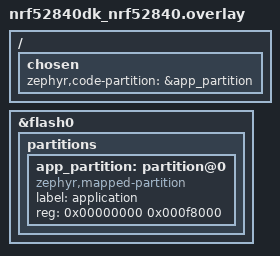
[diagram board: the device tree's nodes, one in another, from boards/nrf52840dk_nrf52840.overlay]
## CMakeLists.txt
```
cmake_minimum_required(VERSION 3.20.0)

find_package(Zephyr REQUIRED HINTS $ENV{ZEPHYR_BASE})
project(ErgoTypeNRF C)

target_compile_definitions(app PRIVATE ERGOTYPE_ZEPHYR=1)

target_include_directories(app PRIVATE
    ${CMAKE_CURRENT_LIST_DIR}
    ${CMAKE_CURRENT_LIST_DIR}/coreJSON/source/include
    ${CMAKE_CURRENT_LIST_DIR}/pointing
    ${CMAKE_CURRENT_LIST_DIR}/pointing/pmw3360
    ${CMAKE_CURRENT_LIST_DIR}/pointing/pmw3389
)

target_compile_options(app PRIVATE
    -iquote${CMAKE_CURRENT_LIST_DIR}/keyd/port
    -iquote${CMAKE_CURRENT_LIST_DIR}/keyd/src
)

set_source_files_properties(keyd/port/config.c PROPERTIES COMPILE_OPTIONS -Wno-comment)

target_sources(app PRIVATE
    src/main.c
    src/keyscan_zephyr.c
    src/log_zephyr.c
    src/pointing_zephyr.c
    src/ui_zephyr.c
    display/ssd1306.c
    coreJSON/source/core_json.c
    keyd/src/keys.c
    keyd/src/string.c
    keyd/src/unicode.c
    keyd/port/config.c
    keyd/port/daemon.c
    keyd/port/evloop.c
    keyd/port/hooks.c
    keyd/port/keyboard.c
    keyd/port/macro.c
    keyd/port/task.c
    keyd/port/vkbd/tusb_hid.c
    keyd/port/vkbd/vkbd.c
    jconfig.c
    pointing/accel/filter.c
    pointing/accel/filter-adaptive.c
    pointing/accel/filter-adaptive-high-dpi.c
    pointing/accel/filter-adaptive-low-dpi.c
    pointing/accel/filter-custom.c
    pointing/accel/filter-flat.c
    pointing/pmw3360/pmw3360.c
    pointing/pmw3360/srom.c
    pointing/pmw3389/pmw3389.c
    pointing/pmw3389/srom.c
    platform/zephyr/ble.c
    platform/zephyr/ble_config.c
    platform/zephyr/ble_log.c
    platform/zephyr/events.c
    platform/zephyr/gpio.c
    platform/zephyr/hid.c
    platform/zephyr/i2c.c
    platform/zephyr/os.c
    platform/zephyr/spi.c
    platform/zephyr/storage.c
    platform/zephyr/time.c
    platform/zephyr/vkbd_events.c
    platform/zephyr/ws2812.c
)
```

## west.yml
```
manifest:
  remotes:
    - name: nrfconnect
      url-base: https://github.com/nrfconnect
  projects:
    - name: nrf
      remote: nrfconnect
      repo-path: sdk-nrf
      revision: v3.4.0
      import: true
  self:
    path: app
```

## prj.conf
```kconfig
CONFIG_MAIN_STACK_SIZE=4096
CONFIG_SYSTEM_WORKQUEUE_STACK_SIZE=2048
CONFIG_HEAP_MEM_POOL_SIZE=32768
CONFIG_THREAD_NAME=y
CONFIG_POLL=y
CONFIG_EVENTS=y
CONFIG_LOG=y
CONFIG_CONSOLE=y
CONFIG_SERIAL=y

CONFIG_GPIO=y
CONFIG_NRFX_PWM=y
CONFIG_NRFX_SPIM=y
CONFIG_NRFX_TWIM=y
CONFIG_BT=y
CONFIG_BT_SMP=y
CONFIG_BT_PERIPHERAL=y
CONFIG_BT_DIS=y
CONFIG_BT_BAS=y
CONFIG_BT_DEVICE_NAME="ErgoTypeNRF"
CONFIG_BT_DEVICE_APPEARANCE=961
CONFIG_BT_SETTINGS=y
CONFIG_BT_L2CAP_TX_MTU=66
CONFIG_BT_BUF_ACL_TX_SIZE=70
CONFIG_BT_BUF_ACL_RX_SIZE=70
CONFIG_FLASH=y
CONFIG_FLASH_MAP=y
CONFIG_FILE_SYSTEM=y
CONFIG_FILE_SYSTEM_LITTLEFS=y
CONFIG_SETTINGS=y
CONFIG_SETTINGS_FILE=y
CONFIG_SETTINGS_FILE_PATH="/lfs/settings"
CONFIG_USE_DT_CODE_PARTITION=y
```

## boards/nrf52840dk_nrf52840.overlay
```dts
/ {
	chosen {
		zephyr,code-partition = &app_partition;
	};
};

&flash0 {
	partitions {
		/delete-node/ partition@0;
		/delete-node/ partition@c000;
		/delete-node/ partition@82000;

		app_partition: partition@0 {
			compatible = "zephyr,mapped-partition";
			label = "application";
			reg = <0x00000000 0x000f8000>;
		};
	};
};
```

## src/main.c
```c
#include <stdbool.h>

#include <zephyr/kernel.h>
#include <zephyr/logging/log.h>

#include "jconfig.h"
#include "platform/ble.h"
#include "platform/events.h"
#include "platform/os.h"
#include "platform/storage.h"
#include "platform/vkbd_events.h"
#include "pointing/pointer.h"
#include "keys.h"
#include "ui/ui.h"

LOG_MODULE_REGISTER(ergotype_nrf, LOG_LEVEL_INF);

extern const char *keyd_overlay_conf;

K_THREAD_STACK_DEFINE(keyscan_stack, 2048);
K_THREAD_STACK_DEFINE(keyd_stack, 8192);
K_THREAD_STACK_DEFINE(pointing_stack, 4096);
K_THREAD_STACK_DEFINE(ui_stack, 2048);
K_THREAD_STACK_DEFINE(vkbd_hid_stack, 4096);

void keyscan_task(void *arg);
uint8_t count_pressed_keys(config_t *config, uint8_t *single_code);
void keyd_task(void *arg);
void vkbd_hid_nkro_task(void *arg);

void on_layout_change(const char *name)
{
    ui_notify_layout(name);
}

static void select_profile(uint8_t code)
{
    switch (code) {
    case KEYD_A:
        keyd_overlay_conf = "android.conf";
        break;
    case KEYD_W:
        keyd_overlay_conf = "windows.conf";
        break;
    case KEYD_M:
        keyd_overlay_conf = "macos.conf";
        break;
    case KEYD_D:
        keyd_overlay_conf = NULL;
        break;
    default:
        return;
    }
}

int main(void)
{
    LOG_INF("ErgoTypeNRF boot");

    int rc = platform_storage_mount();
    if (rc) {
        LOG_WRN("storage mount failed: %d", rc);
    }

    static config_t config;
    bool config_loaded = false;
    rc = parse(&config, "config.json");
    if (rc == 0) {
        uint8_t startup_key = 0;
        uint8_t nr_pressed = count_pressed_keys(&config, &startup_key);
        select_profile(startup_key);
        config_loaded = true;

        LOG_INF("config loaded: rows=%u cols=%u encoders=%u pmw3360=%u pmw3389=%u",
                config.matrix.nr_rows,
                config.matrix.nr_cols,
                config.nr_encoders,
                config.nr_pmw3360,
                config.nr_pmw3389);
        LOG_INF("startup keys: count=%u key=%u", nr_pressed, startup_key);
    } else {
        LOG_WRN("config.json not loaded; keyboard runtime is not started yet");
    }

    rc = platform_ble_start();
    if (rc) {
        LOG_ERR("BLE start failed: %d", rc);
        return rc;
    }

    LOG_INF("BLE advertising started");

    if (config_loaded) {
        rc = platform_input_events_init();
        if (rc) {
            LOG_ERR("input event queue init failed: %d", rc);
            return rc;
        }
        rc = platform_vkbd_events_init();
        if (rc) {
            LOG_ERR("vkbd event queue init failed: %d", rc);
            return rc;
        }

        rc = platform_task_start("keyscan", keyscan_task, &config,
                                 keyscan_stack, K_THREAD_STACK_SIZEOF(keyscan_stack),
                                 K_PRIO_PREEMPT(3));
        if (rc) {
            LOG_ERR("keyscan task start failed: %d", rc);
            return rc;
        }
        if (config.nr_leds != 0 || config.ws2812_pin != -1 || config.ssd1306.i2c_idx != -1) {
            rc = platform_task_start("ui", ui_task, &config,
                                     ui_stack, K_THREAD_STACK_SIZEOF(ui_stack),
                                     K_PRIO_PREEMPT(5));
            if (rc) {
                LOG_ERR("ui task start failed: %d", rc);
                return rc;
            }
        }
        if (config.nr_pmw3360 || config.nr_pmw3389) {
            rc = platform_task_start("pointing", pointing_device_task, &config,
                                     pointing_stack, K_THREAD_STACK_SIZEOF(pointing_stack),
                                     K_PRIO_PREEMPT(1));
            if (rc) {
                LOG_ERR("pointing task start failed: %d", rc);
                return rc;
            }
        }
        rc = platform_task_start("vkbd-hid", vkbd_hid_nkro_task, NULL,
                                 vkbd_hid_stack, K_THREAD_STACK_SIZEOF(vkbd_hid_stack),
                                 K_PRIO_PREEMPT(4));
        if (rc) {
            LOG_ERR("vkbd HID task start failed: %d", rc);
            return rc;
        }
        rc = platform_task_start("keyd", keyd_task, NULL,
                                 keyd_stack, K_THREAD_STACK_SIZEOF(keyd_stack),
                                 K_PRIO_PREEMPT(2));
        if (rc) {
            LOG_ERR("keyd task start failed: %d", rc);
            return rc;
        }
    }

    for (;;) {
        k_sleep(K_SECONDS(60));
    }
}
```

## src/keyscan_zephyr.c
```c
#include <stdbool.h>
#include <stdint.h>

#include "device.h"
#include "jconfig.h"
#include "keys.h"
#include "platform/events.h"
#include "platform/gpio.h"
#include "platform/time.h"

static uint8_t debouncing_time;
static bool debouncing;

typedef struct {
    uint8_t prev;
    int16_t accum;
} encoder_state_t;

static bool is_encoder_channel(const config_t *config, uint8_t row, uint8_t col)
{
    for (uint8_t i = 0; i < config->nr_encoders; ++i) {
        const encoder_t *enc = &config->encoders[i];
        if ((row == enc->a && col == enc->c) || (row == enc->b && col == enc->c))
            return true;
    }
    return false;
}

static inline bool matrix_pressed(const matrix_row_t *matrix, uint8_t row, uint8_t col)
{
    return (matrix[row] & ((matrix_row_t)1 << col)) != 0;
}

static void send_key_tap(uint8_t code)
{
    struct device_event ev = {0};
    ev.type = DEV_KEY;
    ev.code = code;

    ev.pressed = 1;
    platform_input_event_send(&ev, PLATFORM_EVENT_WAIT_FOREVER);
    ev.pressed = 0;
    platform_input_event_send(&ev, PLATFORM_EVENT_WAIT_FOREVER);
}

static void process_encoders(const config_t *config,
                             encoder_state_t *states,
                             const matrix_row_t *raw_matrix)
{
    static const int8_t quad_table[16] = {
        0, -1, 1, 0,
        1, 0, 0, -1,
        -1, 0, 0, 1,
        0, 1, -1, 0,
    };

    for (uint8_t i = 0; i < config->nr_encoders; ++i) {
        const encoder_t *enc = &config->encoders[i];
        encoder_state_t *st = &states[i];

        uint8_t curr = 0;
        if (matrix_pressed(raw_matrix, enc->a, enc->c))
            curr |= 0x1;
        if (matrix_pressed(raw_matrix, enc->b, enc->c))
            curr |= 0x2;

        if (st->prev == 0xFF) {
            st->prev = curr;
            st->accum = 0;
            continue;
        }

        uint8_t idx = (uint8_t)((st->prev << 2) | curr);
        int16_t delta = quad_table[idx];

        st->prev = curr;
        if (delta > 0 && st->accum < 0)
            st->accum = 0;
        else if (delta < 0 && st->accum > 0)
            st->accum = 0;
        st->accum += delta;

        while (st->accum >= (int16_t)enc->div) {
            st->accum -= (int16_t)enc->div;
            send_key_tap(config->matrix.keymap[enc->a][enc->c]);
        }
        while (st->accum <= -(int16_t)enc->div) {
            st->accum += (int16_t)enc->div;
            send_key_tap(config->matrix.keymap[enc->b][enc->c]);
        }
    }
}

static const uint8_t row2col = 0;
static uint8_t col2row = 1;

static void select_row(matrix_t *matrix, uint8_t row)
{
    platform_gpio_output(matrix->gpio_rows[row], false);
}

static void unselect_row(matrix_t *matrix, uint8_t row)
{
    platform_gpio_input_pullup(matrix->gpio_rows[row]);
}

static void select_col(matrix_t *matrix, uint8_t col)
{
    platform_gpio_output(matrix->gpio_cols[col], false);
}

static void unselect_col(matrix_t *matrix, uint8_t col)
{
    platform_gpio_input_pullup(matrix->gpio_cols[col]);
}

void matrix_init(matrix_t *matrix)
{
    if (col2row) {
        for (uint8_t row = 0; row < matrix->nr_rows; row++)
            unselect_row(matrix, row);
        for (uint8_t col = 0; col < matrix->nr_cols; col++)
            unselect_col(matrix, col);
    } else if (row2col) {
        for (uint8_t col = 0; col < matrix->nr_cols; col++)
            unselect_col(matrix, col);
        for (uint8_t row = 0; row < matrix->nr_rows; row++)
            unselect_row(matrix, row);
    } else {
        for (uint8_t row = 0; row < matrix->nr_rows; row++)
            unselect_row(matrix, row);
        for (uint8_t col = 0; col < matrix->nr_cols; col++)
            platform_gpio_input_pullup(matrix->gpio_cols[col]);
    }
}

static inline bool popcount_more_than_one(matrix_row_t rowdata)
{
    rowdata &= rowdata - 1;
    return rowdata != 0;
}

static matrix_row_t get_real_keys(matrix_t *matrix, uint8_t row, matrix_row_t rowdata)
{
    matrix_row_t out = 0;
    for (uint8_t col = 0; col < matrix->nr_cols; col++) {
        if (matrix->keymap[row][col] && (rowdata & ((matrix_row_t)1 << col)))
            out |= ((matrix_row_t)1 << col);
    }
    return out;
}

static bool has_ghost_in_row(matrix_t *matrix, uint8_t row, matrix_row_t rowdata,
                             matrix_row_t *current_matrix)
{
    if (col2row || row2col)
        return false;
    rowdata = get_real_keys(matrix, row, rowdata);
    if (!popcount_more_than_one(rowdata))
        return false;
    for (uint8_t i = 0; i < matrix->nr_rows; i++) {
        if (i != row && popcount_more_than_one(get_real_keys(matrix, i, current_matrix[i]) & rowdata))
            return true;
    }
    return false;
}

void matrix_scan(matrix_t *matrix, matrix_row_t *raw_matrix)
{
    if (col2row) {
        for (uint8_t row = 0; row < matrix->nr_rows; row++) {
            matrix_row_t row_value = 0;
            select_row(matrix, row);
            platform_sleep_us(20);
            for (uint8_t col = 0; col < matrix->nr_cols; col++) {
                int pin_state = platform_gpio_read(matrix->gpio_cols[col]);
                if (pin_state == 0)
                    row_value |= ((matrix_row_t)1 << col);
            }
            unselect_row(matrix, row);
            raw_matrix[row] = row_value;
        }
    } else if (row2col) {
        for (uint8_t col = 0; col < matrix->nr_cols; col++) {
            matrix_row_t col_mask = ((matrix_row_t)1 << col);
            select_col(matrix, col);
            platform_sleep_us(20);
            for (uint8_t row = 0; row < matrix->nr_rows; row++) {
                int pin_state = platform_gpio_read(matrix->gpio_rows[row]);
                if (pin_state == 0)
                    raw_matrix[row] |= col_mask;
                else
                    raw_matrix[row] &= ~col_mask;
            }
            unselect_col(matrix, col);
        }
    } else {
        for (uint8_t row = 0; row < matrix->nr_rows; row++) {
            matrix_row_t row_value = 0;
            uint8_t row_pin = matrix->gpio_rows[row];
            platform_gpio_output(row_pin, false);

            for (uint8_t r = 0; r < matrix->nr_rows; r++) {
                if (r != row)
                    platform_gpio_input_pullup(matrix->gpio_rows[r]);
            }
            platform_sleep_us(20);
            for (uint8_t col = 0; col < matrix->nr_cols; col++) {
                int pin_state = platform_gpio_read(matrix->gpio_cols[col]);
                if (pin_state == 0)
                    row_value |= ((matrix_row_t)1 << col);
            }
            platform_gpio_input_pullup(row_pin);
            raw_matrix[row] = row_value;
        }
    }
}

bool debounce(matrix_row_t *raw_matrix, matrix_row_t *debounced_matrix, uint8_t nr_rows)
{
    static matrix_row_t matrix_debouncing[MAX_GPIOS];
    static uint32_t last_update;
    bool changed = false;

    for (uint8_t i = 0; i < nr_rows; i++) {
        if (matrix_debouncing[i] != raw_matrix[i]) {
            matrix_debouncing[i] = raw_matrix[i];
            debouncing = true;
            last_update = platform_uptime_ms();
        }
    }

    if (debouncing && (platform_uptime_ms() - last_update > debouncing_time)) {
        for (uint8_t i = 0; i < nr_rows; i++) {
            if (debounced_matrix[i] != matrix_debouncing[i]) {
                debounced_matrix[i] = matrix_debouncing[i];
                changed = true;
            }
        }
        debouncing = false;
    }

    return changed;
}

uint8_t count_pressed_keys(config_t *config, uint8_t *single_code)
{
    matrix_row_t raw_matrix[MAX_GPIOS] = {0};
    uint8_t pressed_count = 0;
    uint8_t code = 0;

    matrix_init(&config->matrix);
    matrix_scan(&config->matrix, raw_matrix);

    for (uint8_t row = 0; row < config->matrix.nr_rows; row++) {
        for (uint8_t col = 0; col < config->matrix.nr_cols; col++) {
            if (raw_matrix[row] & ((matrix_row_t)1 << col)) {
                if (!is_encoder_channel(config, row, col)) {
                    pressed_count++;
                    if (pressed_count == 1)
                        code = config->matrix.keymap[row][col];
                }
            }
        }
    }

    *single_code = pressed_count == 1 ? code : 0;
    return pressed_count;
}

void keyscan_task(void *arg)
{
    config_t *config = arg;
    debouncing_time = config->debounce;
    debouncing = debouncing_time > 0;
    static matrix_row_t raw_matrix[MAX_GPIOS];
    static matrix_row_t debounced_matrix[MAX_GPIOS];
    static matrix_row_t previous_debounced_matrix[MAX_GPIOS];
    static encoder_state_t encoder_states[MAX_ENCODERS];
    struct device_event devev = {
        .type = DEV_KEY,
    };

    matrix_init(&config->matrix);
    for (uint8_t i = 0; i < MAX_ENCODERS; ++i) {
        encoder_states[i].prev = 0xFF;
        encoder_states[i].accum = 0;
    }

    for (;;) {
        uint32_t started = platform_uptime_ms();
        matrix_scan(&config->matrix, raw_matrix);
        if (config->nr_encoders > 0)
            process_encoders(config, encoder_states, raw_matrix);

        bool debounced_changed = debounce(raw_matrix, debounced_matrix, config->matrix.nr_rows);
        if (debounced_changed) {
            for (uint8_t row = 0; row < config->matrix.nr_rows; row++) {
                matrix_row_t changed_keys = debounced_matrix[row] ^ previous_debounced_matrix[row];
                if (!changed_keys) {
                    previous_debounced_matrix[row] = debounced_matrix[row];
                    continue;
                }
                if (has_ghost_in_row(&config->matrix, row, debounced_matrix[row], debounced_matrix)) {
                    debounced_matrix[row] = 0;
                    previous_debounced_matrix[row] = debounced_matrix[row];
                    continue;
                }
                for (uint8_t col = 0; col < config->matrix.nr_cols; col++) {
                    matrix_row_t col_mask = ((matrix_row_t)1 << col);
                    if (!(changed_keys & col_mask))
                        continue;
                    if (is_encoder_channel(config, row, col))
                        continue;

                    devev.pressed = (debounced_matrix[row] & col_mask) != 0;
                    devev.code = config->matrix.keymap[row][col];
                    platform_input_event_send(&devev, PLATFORM_EVENT_WAIT_FOREVER);
                }
                previous_debounced_matrix[row] = debounced_matrix[row];
            }
        }

        uint32_t elapsed = platform_uptime_ms() - started;
        if (elapsed < (uint32_t)config->scan_period)
            platform_sleep_ms((uint32_t)config->scan_period - elapsed);
    }
}
```

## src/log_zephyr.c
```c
#include "log.h"

#include <stdbool.h>
#include <stdio.h>
#include <string.h>

#include <zephyr/sys/printk.h>

#include "platform/ble_log.h"
#include "ui/ui.h"

int log_level = 0;
int suppress_colours = 1;

static void strip_markup(const char *input, char *output, size_t output_size)
{
    size_t out = 0;
    bool inside_markup = false;

    for (size_t i = 0; input[i] != '\0' && out + 1u < output_size; ++i) {
        if (input[i + 1u] == '{' && strchr("rgybmcw", input[i])) {
            inside_markup = true;
            ++i;
            continue;
        }
        if (input[i] == '}' && inside_markup) {
            inside_markup = false;
            continue;
        }
        output[out++] = input[i];
    }

    output[out] = '\0';
}

void _msg(int level, log_kind_t kind, const char *fmt, ...)
{
    if (level > log_level)
        return;

    switch (kind) {
    case LOG_KIND_WARN:
        ui_notify_warn();
        break;
    case LOG_KIND_ERR:
        ui_notify_err();
        break;
    case LOG_KIND_MSG:
        break;
    }

    char clean_fmt[160];
    char line[160];
    strip_markup(fmt, clean_fmt, sizeof(clean_fmt));

    va_list ap;
    va_start(ap, fmt);
    int n = vsnprintf(line, sizeof(line), clean_fmt, ap);
    va_end(ap);

    if (n <= 0)
        return;

    size_t length = (size_t)n < sizeof(line) ? (size_t)n : sizeof(line) - 1u;
    printk("%s", line);
    platform_ble_log_write(line, length);
}
```

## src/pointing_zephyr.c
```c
#include <stdint.h>

#include <zephyr/kernel.h>
#include <zephyr/sys/atomic.h>

#include "accel/filter.h"
#include "device.h"
#include "jconfig.h"
#include "log.h"
#include "platform/events.h"
#include "platform/gpio.h"
#include "platform/spi.h"
#include "platform/time.h"
#include "pointing/pointer.h"
#include "pmw3360.h"
#include "pmw3389.h"

static struct k_poll_signal motion_signal;
static atomic_t motion_bits;

static int32_t x125pct(int32_t value)
{
    int32_t magnitude = value < 0 ? -value : value;
    // Add 25%: shifting the magnitude right by 2 divides it by 4.
    magnitude += magnitude >> 2;

    return value < 0 ? -magnitude : magnitude;
}

static int32_t scaled_to_q10(int32_t value, int32_t scale)
{
    int32_t whole = value / scale;
    int32_t rem = value % scale;
    int32_t q10 = whole * Q10_ONE;

    if (rem < 0)
        q10 -= ((-rem * Q10_ONE) + scale / 2) / scale;
    else
        q10 += (rem * Q10_ONE + scale / 2) / scale;

    return q10;
}

static void accel_prepare(accel_profile_cfg_t *accel)
{
    switch (accel->profile) {
    case ACCEL_PROFILE_NONE:
        return;
    case ACCEL_PROFILE_FLAT:
    case ACCEL_PROFILE_ADAPTIVE:
        accel->speed = scaled_to_q10(accel->speed, accel->scale);
        return;
    case ACCEL_PROFILE_CUSTOM:
        return;
    }
}

static void motion_irq(platform_gpio_t pin, void *user)
{
    (void)pin;

    uint32_t bits = (uint32_t)(uintptr_t)user;
    atomic_or(&motion_bits, (atomic_val_t)bits);
    k_poll_signal_raise(&motion_signal, 1);
}

void pointing_motion_irq_init(void *task_handle, int8_t mot_pin, uint8_t sensor_idx)
{
    (void)task_handle;

    uint32_t bit = 1u << sensor_idx;
    platform_gpio_irq_falling(mot_pin, motion_irq, (void *)(uintptr_t)bit);
}

static void spi_bus_init_once(uint8_t bus, const config_t *config)
{
    platform_spi_init(bus,
                      config->spi[bus].sck,
                      config->spi[bus].mosi,
                      config->spi[bus].miso,
                      config->spi[bus].baud);
}

void pointing_device_task(void *arg)
{
    config_t *config = arg;
    struct filter_state *pmw3360_filters = NULL;
    struct filter_state *pmw3389_filters = NULL;
    accel_prepare(&config->move_accel);
    accel_prepare(&config->scroll_accel);

    if (config->nr_pmw3360) {
        pmw3360_filters = k_malloc(sizeof(*pmw3360_filters) * config->nr_pmw3360);
        __ASSERT_NO_MSG(pmw3360_filters);
    }

    if (config->nr_pmw3389) {
        pmw3389_filters = k_malloc(sizeof(*pmw3389_filters) * config->nr_pmw3389);
        __ASSERT_NO_MSG(pmw3389_filters);
    }

    k_poll_signal_init(&motion_signal);

    for (uint8_t bus = 0; bus < MAX_SPI; ++bus) {
        if (config->spi_mask & (uint8_t)(1u << bus))
            spi_bus_init_once(bus, config);
    }

    for (uint8_t i = 0; i < config->nr_pmw3360; ++i) {
        pmw3360_init(&config->pmw3360[i]);
        pmw3360_set_cpi(&config->pmw3360[i]);
        uint8_t role = config->pmw3360[i].role;
        filter_init(&pmw3360_filters[i],
                    role == SENSOR_ROLE_SCROLL ? &config->scroll_accel : &config->move_accel,
                    config->pmw3360[i].cpi);
        pointing_motion_irq_init(NULL, config->pmw3360[i].irq, i);
    }

    for (uint8_t i = 0; i < config->nr_pmw3389; ++i) {
        pmw3389_init(&config->pmw3389[i]);
        pmw3389_set_cpi(&config->pmw3389[i]);
        uint8_t role = config->pmw3389[i].role;
        filter_init(&pmw3389_filters[i],
                    role == SENSOR_ROLE_SCROLL ? &config->scroll_accel : &config->move_accel,
                    config->pmw3389[i].cpi);
        pointing_motion_irq_init(NULL, config->pmw3389[i].irq, (uint8_t)(MAX_PMW3360 + i));
    }

    struct k_poll_event event = K_POLL_EVENT_INITIALIZER(K_POLL_TYPE_SIGNAL,
                                                         K_POLL_MODE_NOTIFY_ONLY,
                                                         &motion_signal);

    for (;;) {
        k_poll(&event, 1, K_FOREVER);
        k_poll_signal_reset(&motion_signal);
        event.state = K_POLL_STATE_NOT_READY;

        platform_sleep_ms(1);

        uint32_t bits = (uint32_t)atomic_set(&motion_bits, 0);
        int mouse_dx_sum = 0;
        int mouse_dy_sum = 0;
        int scroll_dx_sum = 0;
        int scroll_dy_sum = 0;
        struct device_event devev = {0};

        for (uint8_t i = 0; i < config->nr_pmw3360; ++i) {
            if (bits && !(bits & (1u << i)))
                continue;
            int16_t dx = 0;
            int16_t dy = 0;
            pmw3360_get_deltas(&config->pmw3360[i], &dx, &dy);
            // Temporary transform for the current trackball prototype, whose sensor is mounted at 30 degrees.
            // This may move to config if per-device coordinate transforms are needed.
            int32_t x = x125pct(dx);
            int32_t y = -dy;
            uint8_t role = config->pmw3360[i].role;
            filter_process(&pmw3360_filters[i], &x, &y);
            if (role == SENSOR_ROLE_SCROLL) {
                scroll_dx_sum += x;
                scroll_dy_sum += y;
            } else {
                mouse_dx_sum += x;
                mouse_dy_sum += y;
            }
        }

        for (uint8_t i = 0; i < config->nr_pmw3389; ++i) {
            if (bits && !(bits & (1u << (MAX_PMW3360 + i))))
                continue;
            int16_t dx = 0;
            int16_t dy = 0;
            pmw3389_get_deltas(&config->pmw3389[i], &dx, &dy);
            // Temporary transform for the current trackball prototype, whose sensor is mounted at 30 degrees.
            // This may move to config if per-device coordinate transforms are needed.
            int32_t x = x125pct(dx);
            int32_t y = -dy;
            uint8_t role = config->pmw3389[i].role;
            filter_process(&pmw3389_filters[i], &x, &y);
            if (role == SENSOR_ROLE_SCROLL) {
                scroll_dx_sum += x;
                scroll_dy_sum += y;
            } else {
                mouse_dx_sum += x;
                mouse_dy_sum += y;
            }
        }

        if (mouse_dx_sum || mouse_dy_sum) {
            devev.type = DEV_MOUSE_MOVE;
            devev.x = mouse_dx_sum;
            devev.y = mouse_dy_sum;
            platform_input_event_send(&devev, PLATFORM_EVENT_WAIT_FOREVER);
        }
        if (scroll_dx_sum || scroll_dy_sum) {
            devev.type = DEV_MOUSE_SCROLL;
            devev.x = scroll_dx_sum;
            devev.y = scroll_dy_sum;
            platform_input_event_send(&devev, PLATFORM_EVENT_WAIT_FOREVER);
        }
    }
}
```

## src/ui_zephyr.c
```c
#include "ui/ui.h"

#include <stdio.h>
#include <string.h>

#include <zephyr/kernel.h>

#include "display/px6x8_font.h"
#include "display/ssd1306.h"
#include "jconfig.h"
#include "led/ws2812.h"
#include "platform/gpio.h"
#include "platform/i2c.h"

#define UI_STEP_MS 100u
#define UI_TITLE_LEN (sizeof(ui_title) - 1u)
#define UI_TITLE_WIDTH_PX (UI_TITLE_LEN * 6u)
#define UI_TITLE_WIN_COLS 4u
#define UI_TITLE_WIN_PX (UI_TITLE_WIN_COLS * 6u)
#define UI_STATUS_MODE_LEN 3u
#define UI_STATUS_MODE_COL (UI_TITLE_WIN_COLS + 1u)
#define UI_STATUS_CDC_LEN 3u
#define UI_STATUS_CDC_WARN_PX 2u
#define UI_STATUS_CDC_WARN_X (128u - UI_STATUS_CDC_WARN_PX)
#define UI_STATUS_CDC_COL ((UI_STATUS_CDC_WARN_X / 6u) - UI_STATUS_CDC_LEN)
#define UI_STATUS_LAYOUT_X ((UI_STATUS_MODE_COL + UI_STATUS_MODE_LEN + 1u) * 6u)
#define UI_STATUS_LAYOUT_PX ((UI_STATUS_CDC_COL * 6u) - UI_STATUS_LAYOUT_X)
#define UI_LAYOUT_NAME_LEN 32u
#define UI_LAYOUT_SPAN_PX (UI_LAYOUT_NAME_LEN * 6u)
#define UI_LAYOUT_WIN_PX UI_STATUS_LAYOUT_PX
#define UI_OUTPUT_EVENTS_ROW0_WITH_STATUS 2u
#define UI_OUTPUT_EVENTS_ROWS_WITH_STATUS 6u
#define UI_OUTPUT_EVENTS_ROW0_NO_STATUS 1u
#define UI_OUTPUT_EVENTS_ROWS_NO_STATUS 7u
#define UI_OUTPUT_EVENTS_MAX_ROWS UI_OUTPUT_EVENTS_ROWS_NO_STATUS

enum {
    UI_EVT_LED0            = 1u << 0,
    UI_EVT_LED1            = 1u << 1,
    UI_EVT_WS2812          = 1u << 2,
    UI_EVT_SCREEN          = 1u << 3,
    UI_EVT_STATUS          = 1u << 4,
    UI_EVT_TICK            = 1u << 5,
    UI_EVT_OUTPUT_EVENTS   = 1u << 6,
    UI_EVT_LAYOUT          = 1u << 7,
};

ui_task_handle_t ui_handle;

static struct k_event ui_events;
static volatile uint32_t ui_led_pattern[MAX_LED];
static volatile bool ui_led_loop[MAX_LED];
static volatile uint32_t ui_ws2812_pattern;
static volatile bool ui_ws2812_loop;
static volatile uint32_t ui_ws2812_color;
static volatile uint32_t ui_warn_count;
static volatile uint32_t ui_err_count;
static volatile uint32_t ui_cdc_drop_writes;
static volatile uint32_t ui_cdc_drop_bytes;
static volatile bool ui_cdc_connected;
static char ui_layout_name[UI_LAYOUT_NAME_LEN + 1u];
static char ui_output_events[UI_OUTPUT_EVENTS_MAX_ROWS][UI_OUTPUT_EVENT_LINE_LEN + 1u];
static volatile uint8_t ui_output_events_head;
static volatile uint8_t ui_output_events_count;

static const char ui_title[] = "ErgoType";

static inline uint32_t rot_r32(uint32_t v)
{
    return (v >> 1) | (v << 31);
}

static void ui_tick_timer_cb(struct k_timer *timer)
{
    (void)timer;
    k_event_post(&ui_events, UI_EVT_TICK);
}

K_TIMER_DEFINE(ui_tick_timer, ui_tick_timer_cb, NULL);

void ui_led_set_pattern(uint8_t led_idx, uint32_t pattern, bool loop)
{
    ui_led_pattern[led_idx] = pattern;
    ui_led_loop[led_idx] = loop;
    if (ui_handle)
        k_event_post(&ui_events, led_idx ? UI_EVT_LED1 : UI_EVT_LED0);
}

void ui_ws2812_set(uint32_t color, uint32_t pattern, bool loop)
{
    ui_ws2812_color = color;
    ui_ws2812_pattern = pattern;
    ui_ws2812_loop = loop;
    if (ui_handle)
        k_event_post(&ui_events, UI_EVT_WS2812);
}

void ui_notify_warn(void)
{
    ui_warn_count++;
}

void ui_notify_err(void)
{
    ui_err_count++;
}

void ui_notify_cdc_drop(size_t bytes)
{
    ui_cdc_drop_writes++;
    ui_cdc_drop_bytes += (uint32_t)bytes;
}

void ui_notify_cdc_connected(void)
{
    ui_cdc_connected = true;
}

void ui_notify_cdc_disconnected(void)
{
    ui_cdc_connected = false;
}

void ui_notify_output_event(const char *s)
{
    if (!ui_handle)
        return;

    char line[UI_OUTPUT_EVENT_LINE_LEN + 1u] = {0};

    (void)snprintf(line, sizeof(line), "%s", s);

    memcpy(ui_output_events[ui_output_events_head], line, sizeof(line));
    ui_output_events_head++;
    if (ui_output_events_head == UI_OUTPUT_EVENTS_MAX_ROWS)
        ui_output_events_head = 0;
    if (ui_output_events_count != UI_OUTPUT_EVENTS_MAX_ROWS)
        ui_output_events_count++;

    k_event_post(&ui_events, UI_EVT_OUTPUT_EVENTS);
}

void ui_notify_layout(const char *name)
{
    (void)snprintf(ui_layout_name, sizeof(ui_layout_name), "%s", name);

    if (ui_handle)
        k_event_post(&ui_events, UI_EVT_LAYOUT);
}

typedef enum {
    UI_SCREEN_BOOT = 0,
    UI_SCREEN_STATUS = 1,
} ui_screen_t;

typedef struct {
    const ssd1306_cfg_t *disp;
    ui_screen_t screen;
    bool cdc_connected;
    uint32_t err_count;
    uint32_t warn_count;
    uint32_t cdc_drop_writes;
    uint32_t cdc_drop_bytes;
    uint8_t title_span[UI_TITLE_WIDTH_PX];
    uint8_t layout_span[UI_LAYOUT_SPAN_PX];
    uint8_t layout_span_len;
    uint8_t layout_offset;
    int8_t layout_dir;
    bool layout_scroll;
} ui_state_t;

static void ui_render_boot(ui_state_t *ui)
{
    const char *line0 = "ErgoType";
    const char *line1 = "firmware";
    const uint8_t cols4x8 = ui->disp->width / 4u;
    const uint8_t cols6x8 = ui->disp->width / 6u;
    uint8_t col0 = (cols6x8 - strlen(line0)) / 2u;
    uint8_t col1 = (cols4x8 - strlen(line1)) / 2u;

    ssd1306_clear(ui->disp);
    ssd1306_putn6x8(ui->disp, 2, col0, line0, strlen(line0));
    ssd1306_putn4x8(ui->disp, 4, col1, line1, strlen(line1));
}

static void ui_read_stats(ui_state_t *ui)
{
    ui->err_count = ui_err_count;
    ui->warn_count = ui_warn_count;
    ui->cdc_drop_writes = ui_cdc_drop_writes;
    ui->cdc_drop_bytes = ui_cdc_drop_bytes;
}

static void ui_draw_diagnostics(ui_state_t *ui)
{
    char line[22];

    ssd1306_clear_page(ui->disp, 1);
    if (ui->err_count || ui->warn_count || ui_output_events_count == 0) {
        (void)snprintf(line, sizeof(line), "err=%lu warn=%lu",
                       (unsigned long)ui->err_count, (unsigned long)ui->warn_count);
        ssd1306_putn4x8(ui->disp, 1, 0, line, strlen(line));
    }
}

static void ui_prepare_layout_span(ui_state_t *ui)
{
    size_t len = strlen(ui_layout_name);

    memset(ui->layout_span, 0, sizeof(ui->layout_span));
    for (size_t i = 0; i < len; ++i)
        memcpy(&ui->layout_span[i * 6u], px6x8_glyphs[(uint8_t)ui_layout_name[i]], 6u);

    ui->layout_span_len = (uint8_t)(len * 6u);
    ui->layout_scroll = len * 6u > UI_LAYOUT_WIN_PX;
    ui->layout_offset = 0;
    ui->layout_dir = 1;
}

static void ui_draw_layout(ui_state_t *ui)
{
    uint8_t span[UI_LAYOUT_WIN_PX] = {0};
    uint8_t n = ui->layout_span_len;

    if (n > UI_LAYOUT_WIN_PX)
        n = UI_LAYOUT_WIN_PX;
    memcpy(span, ui->layout_span + ui->layout_offset, n);
    ssd1306_write_page_span(ui->disp, 0, UI_STATUS_LAYOUT_X, span, UI_LAYOUT_WIN_PX);
}

static void ui_draw_output_events(ui_state_t *ui)
{
    char lines[UI_OUTPUT_EVENTS_MAX_ROWS][UI_OUTPUT_EVENT_LINE_LEN + 1u] = {0};
    const uint8_t row0 = (ui->err_count || ui->warn_count || ui_output_events_count == 0) ? UI_OUTPUT_EVENTS_ROW0_WITH_STATUS
                                                                                          : UI_OUTPUT_EVENTS_ROW0_NO_STATUS;
    const uint8_t rows = (ui->err_count || ui->warn_count || ui_output_events_count == 0) ? UI_OUTPUT_EVENTS_ROWS_WITH_STATUS
                                                                                          : UI_OUTPUT_EVENTS_ROWS_NO_STATUS;
    uint8_t head = 0;
    uint8_t count = 0;

    head = ui_output_events_head;
    count = ui_output_events_count;
    if (count > rows) {
        count = rows;
        ui_output_events_count = rows;
    }
    for (uint8_t i = 0; i < count; ++i) {
        uint8_t idx = (uint8_t)(head + UI_OUTPUT_EVENTS_MAX_ROWS - count + i);
        if (idx >= UI_OUTPUT_EVENTS_MAX_ROWS)
            idx -= UI_OUTPUT_EVENTS_MAX_ROWS;
        memcpy(lines[i], ui_output_events[idx], sizeof(lines[i]));
    }

    for (uint8_t i = 0; i < rows; ++i) {
        ssd1306_clear_page(ui->disp, row0 + i);
        ssd1306_putn4x8(ui->disp, row0 + i, 0, lines[i], strlen(lines[i]));
    }
}

static void ui_update_status_indicators(ui_state_t *ui)
{
    const uint8_t warn_span[UI_STATUS_CDC_WARN_PX] = {0x5Fu, 0x00u};
    const uint8_t clear_span[UI_STATUS_CDC_WARN_PX] = {0x00u, 0x00u};

    if (ui->cdc_connected != ui_cdc_connected) {
        ui->cdc_connected = ui_cdc_connected;
        const char *s = ui->cdc_connected ? "CDC" : "   ";
        ssd1306_putn6x8(ui->disp, 0, UI_STATUS_CDC_COL, s, UI_STATUS_CDC_LEN);
        ssd1306_write_page_span(ui->disp, 0, UI_STATUS_CDC_WARN_X,
                                (ui->cdc_connected && ui_cdc_drop_writes) ? warn_span : clear_span,
                                UI_STATUS_CDC_WARN_PX);
    }

    if (ui->err_count != ui_err_count ||
        ui->warn_count != ui_warn_count ||
        ui->cdc_drop_writes != ui_cdc_drop_writes ||
        ui->cdc_drop_bytes != ui_cdc_drop_bytes) {
        ui_read_stats(ui);
        ui_draw_diagnostics(ui);
        ui_draw_output_events(ui);
        ssd1306_write_page_span(ui->disp, 0, UI_STATUS_CDC_WARN_X,
                                (ui->cdc_connected && ui->cdc_drop_writes) ? warn_span : clear_span,
                                UI_STATUS_CDC_WARN_PX);
    }
}

static void ui_render_status_screen(ui_state_t *ui)
{
    ui_read_stats(ui);

    ssd1306_clear(ui->disp);
    ssd1306_putn6x8(ui->disp, 0, UI_STATUS_MODE_COL, "BLE", UI_STATUS_MODE_LEN);
    ui->cdc_connected = ui_cdc_connected;
    ssd1306_putn6x8(ui->disp, 0, UI_STATUS_CDC_COL, ui->cdc_connected ? "CDC" : "   ", UI_STATUS_CDC_LEN);
    const uint8_t warn_span[UI_STATUS_CDC_WARN_PX] = {0x5Fu, 0x00u};
    const uint8_t clear_span[UI_STATUS_CDC_WARN_PX] = {0x00u, 0x00u};
    ssd1306_write_page_span(ui->disp, 0, UI_STATUS_CDC_WARN_X,
                            (ui->cdc_connected && ui->cdc_drop_writes) ? warn_span : clear_span,
                            UI_STATUS_CDC_WARN_PX);

    for (size_t i = 0; i < UI_TITLE_LEN; ++i)
        memcpy(&ui->title_span[i * 6u], px6x8_glyphs[(uint8_t)ui_title[i]], 6u);
    for (uint8_t x = 0; x < UI_TITLE_WIN_PX; x += 4u)
        ssd1306_write_page_span(ui->disp, 0, x, &ui->title_span[x], 4u);

    ui_prepare_layout_span(ui);
    ui_draw_layout(ui);
    ui_draw_diagnostics(ui);
    ui_draw_output_events(ui);
}

static void ui_spin_status_title(ui_state_t *ui)
{
    const uint8_t first = ui->title_span[0];
    memmove(ui->title_span, ui->title_span + 1u, UI_TITLE_WIDTH_PX - 1u);
    ui->title_span[UI_TITLE_WIDTH_PX - 1u] = first;
    for (uint8_t x = 0; x < UI_TITLE_WIN_PX; x += 4u)
        ssd1306_write_page_span(ui->disp, 0, x, &ui->title_span[x], 4u);
}

static void ui_bounce_status_layout(ui_state_t *ui)
{
    if (!ui->layout_scroll)
        return;

    uint8_t max_offset = ui->layout_span_len - UI_LAYOUT_WIN_PX;

    if (ui->layout_offset == 0)
        ui->layout_dir = 1;
    else if (ui->layout_offset == max_offset)
        ui->layout_dir = -1;

    ui->layout_offset = (uint8_t)(ui->layout_offset + ui->layout_dir);
    ui_draw_layout(ui);
}

static void ui_tick_status_screen(ui_state_t *ui)
{
    ui_update_status_indicators(ui);
    ui_spin_status_title(ui);
    ui_bounce_status_layout(ui);
}

void ui_task(void *pvParameters)
{
    const config_t *config = (const config_t *)pvParameters;

    k_event_init(&ui_events);
    ui_handle = k_current_get();

    ui_state_t ui = {0};

    for (uint8_t i = 0; i < config->nr_leds; ++i)
        platform_gpio_output(config->led_pins[i], false);

    bool has_ws2812 = config->ws2812_pin != -1 && ws2812_hw_init(config->ws2812_pin);

    bool has_display = config->ssd1306.i2c_idx != -1;
    if (has_display) {
        for (uint8_t bus = 0; bus < MAX_I2C; ++bus) {
            if (!(config->i2c_mask & (uint8_t)(1u << bus)))
                continue;
            platform_i2c_init(bus,
                              config->i2c[bus].sda,
                              config->i2c[bus].scl,
                              config->i2c[bus].baud);
        }

        ui.disp = &config->ssd1306;
        ssd1306_init(ui.disp);
        ui.screen = UI_SCREEN_BOOT;
        ui_render_boot(&ui);
        k_sleep(K_MSEC(300u));
        ui.screen = UI_SCREEN_STATUS;
        ui_render_status_screen(&ui);
    }

    uint32_t led_ring[MAX_LED] = {0};
    bool led_loop[MAX_LED] = {0};
    for (uint8_t i = 0; i < config->nr_leds; ++i) {
        led_ring[i] = ui_led_pattern[i];
        led_loop[i] = ui_led_loop[i];
    }

    uint32_t ws_ring = ui_ws2812_pattern;
    bool ws_loop = ui_ws2812_loop;
    uint32_t ws_color = ui_ws2812_color;

    k_timer_start(&ui_tick_timer, K_MSEC(UI_STEP_MS), K_MSEC(UI_STEP_MS));

    for (;;) {
        uint32_t events = k_event_wait(&ui_events,
                                       UI_EVT_LED0 | UI_EVT_LED1 | UI_EVT_WS2812 |
                                       UI_EVT_SCREEN | UI_EVT_STATUS | UI_EVT_TICK |
                                       UI_EVT_OUTPUT_EVENTS | UI_EVT_LAYOUT,
                                       true,
                                       K_FOREVER);

        if (events & UI_EVT_LED0) {
            led_ring[0] = ui_led_pattern[0];
            led_loop[0] = ui_led_loop[0];
        }
        if (events & UI_EVT_LED1) {
            led_ring[1] = ui_led_pattern[1];
            led_loop[1] = ui_led_loop[1];
        }
        if (events & UI_EVT_WS2812) {
            ws_ring = ui_ws2812_pattern;
            ws_loop = ui_ws2812_loop;
            ws_color = ui_ws2812_color;
        }
        if (has_display) {
            if (events & UI_EVT_SCREEN) {
                switch (ui.screen) {
                case UI_SCREEN_STATUS:
                    ui_render_status_screen(&ui);
                    break;
                default:
                    break;
                }
            }
            if ((events & UI_EVT_OUTPUT_EVENTS) && ui.screen == UI_SCREEN_STATUS)
                ui_draw_output_events(&ui);
            if ((events & UI_EVT_LAYOUT) && ui.screen == UI_SCREEN_STATUS) {
                ui_prepare_layout_span(&ui);
                ui_draw_layout(&ui);
            }
            if ((events & UI_EVT_STATUS) && ui.screen == UI_SCREEN_STATUS)
                ui_update_status_indicators(&ui);
        }

        if (!(events & UI_EVT_TICK))
            continue;

        for (uint8_t i = 0; i < config->nr_leds; ++i) {
            platform_gpio_write(config->led_pins[i], (led_ring[i] & 0x01u) != 0);
            led_ring[i] = led_loop[i] ? rot_r32(led_ring[i]) : (led_ring[i] >> 1);
        }

        if (has_ws2812) {
            ws2812_hw_put((ws_ring & 0x01u) ? ws_color : WS2812_OFF);
            ws_ring = ws_loop ? rot_r32(ws_ring) : (ws_ring >> 1);
        }

        if (has_display && ui.screen == UI_SCREEN_STATUS)
            ui_tick_status_screen(&ui);
    }
}
```
